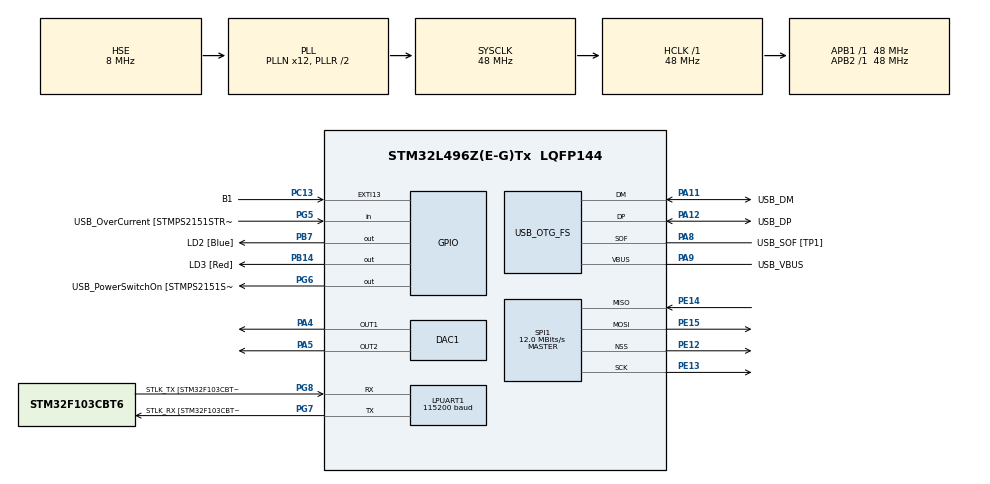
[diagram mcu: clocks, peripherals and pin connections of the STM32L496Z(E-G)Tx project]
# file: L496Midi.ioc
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DAC1.DAC_Channel-DAC_OUT2=DAC_CHANNEL_2
Dma.DAC_CH1.3.Direction=DMA_MEMORY_TO_PERIPH
Dma.DAC_CH1.3.Instance=DMA2_Channel4
Dma.DAC_CH1.3.MemDataAlignment=DMA_MDATAALIGN_HALFWORD
Dma.DAC_CH1.3.MemInc=DMA_MINC_ENABLE
Dma.DAC_CH1.3.Mode=DMA_NORMAL
Dma.DAC_CH1.3.PeriphDataAlignment=DMA_PDATAALIGN_HALFWORD
Dma.DAC_CH1.3.PeriphInc=DMA_PINC_DISABLE
Dma.DAC_CH1.3.Priority=DMA_PRIORITY_LOW
Dma.DAC_CH2.4.Direction=DMA_MEMORY_TO_PERIPH
Dma.DAC_CH2.4.Instance=DMA1_Channel4
Dma.DAC_CH2.4.MemDataAlignment=DMA_MDATAALIGN_HALFWORD
Dma.DAC_CH2.4.MemInc=DMA_MINC_ENABLE
Dma.DAC_CH2.4.Mode=DMA_NORMAL
Dma.DAC_CH2.4.PeriphDataAlignment=DMA_PDATAALIGN_HALFWORD
Dma.DAC_CH2.4.PeriphInc=DMA_PINC_DISABLE
Dma.DAC_CH2.4.Priority=DMA_PRIORITY_LOW
Dma.LPUART_TX.2.Direction=DMA_MEMORY_TO_PERIPH
Dma.LPUART_TX.2.Instance=DMA2_Channel6
Dma.LPUART_TX.2.MemDataAlignment=DMA_MDATAALIGN_BYTE
Dma.LPUART_TX.2.MemInc=DMA_MINC_ENABLE
Dma.LPUART_TX.2.Mode=DMA_CIRCULAR
Dma.LPUART_TX.2.PeriphDataAlignment=DMA_PDATAALIGN_BYTE
Dma.LPUART_TX.2.PeriphInc=DMA_PINC_DISABLE
Dma.LPUART_TX.2.Priority=DMA_PRIORITY_LOW
Dma.Request0=SPI1_RX
Dma.Request1=SPI1_TX
Dma.Request2=LPUART_TX
Dma.Request3=DAC_CH1
Dma.Request4=DAC_CH2
Dma.SPI1_RX.0.Direction=DMA_PERIPH_TO_MEMORY
Dma.SPI1_RX.0.Instance=DMA1_Channel2
Dma.SPI1_RX.0.MemDataAlignment=DMA_MDATAALIGN_BYTE
Dma.SPI1_RX.0.MemInc=DMA_MINC_ENABLE
Dma.SPI1_RX.0.Mode=DMA_NORMAL
Dma.SPI1_RX.0.PeriphDataAlignment=DMA_PDATAALIGN_BYTE
Dma.SPI1_RX.0.PeriphInc=DMA_PINC_DISABLE
Dma.SPI1_RX.0.Priority=DMA_PRIORITY_HIGH
Dma.SPI1_TX.1.Direction=DMA_MEMORY_TO_PERIPH
Dma.SPI1_TX.1.Instance=DMA1_Channel3
Dma.SPI1_TX.1.MemDataAlignment=DMA_MDATAALIGN_BYTE
Dma.SPI1_TX.1.MemInc=DMA_MINC_ENABLE
Dma.SPI1_TX.1.Mode=DMA_NORMAL
Dma.SPI1_TX.1.PeriphDataAlignment=DMA_PDATAALIGN_BYTE
Dma.SPI1_TX.1.PeriphInc=DMA_PINC_DISABLE
Dma.SPI1_TX.1.Priority=DMA_PRIORITY_HIGH
LPUART1.BaudRate=115200
LPUART1.Parity=UART_PARITY_EVEN
LPUART1.WordLength=UART_WORDLENGTH_9B
Mcu.Family=STM32L4
Mcu.Name=STM32L496Z(E-G)Tx
Mcu.Package=LQFP144
NVIC.DMA1_Channel2_IRQn=true\:0\:0\:false\:false\:true\:false
NVIC.DMA1_Channel3_IRQn=true\:0\:0\:false\:false\:true\:false
NVIC.DMA1_Channel4_IRQn=true\:0\:0\:false\:false\:true\:false
NVIC.DMA2_Channel4_IRQn=true\:0\:0\:false\:false\:true\:false
NVIC.DMA2_Channel6_IRQn=true\:0\:0\:false\:false\:true\:false
NVIC.OTG_FS_IRQn=true\:0\:0\:false\:false\:true\:false
NVIC.PriorityGroup=NVIC_PRIORITYGROUP_4
PA11.GPIO_Label=USB_DM
PA11.Mode=Device_Only
PA11.Signal=USB_OTG_FS_DM
PA12.GPIO_Label=USB_DP
PA12.Mode=Device_Only
PA12.Signal=USB_OTG_FS_DP
PA13\ (JTMS/SWDIO).GPIO_Label=TMS
PA13\ (JTMS/SWDIO).Mode=Trace_Asynchronous_SW
PA13\ (JTMS/SWDIO).Signal=SYS_JTMS-SWDIO
PA14\ (JTCK/SWCLK).GPIO_Label=TCK
PA14\ (JTCK/SWCLK).Mode=Trace_Asynchronous_SW
PA14\ (JTCK/SWCLK).Signal=SYS_JTCK-SWCLK
PA4.Signal=COMP_DAC11_group
PA5.Signal=COMP_DAC12_group
PA8.GPIO_Label=USB_SOF [TP1]
PA8.Mode=Activate_SOF_FS
PA8.Signal=USB_OTG_FS_SOF
PA9.GPIO_Label=USB_VBUS
PA9.Mode=Activate_VBUS
PA9.Signal=USB_OTG_FS_VBUS
PB14.GPIO_Label=LD3 [Red]
PB14.Signal=GPIO_Output
PB3\ (JTDO/TRACESWO).GPIO_Label=SWO
PB3\ (JTDO/TRACESWO).Mode=Trace_Asynchronous_SW
PB3\ (JTDO/TRACESWO).Signal=SYS_JTDO-SWO
PB7.GPIO_Label=LD2 [Blue]
PB7.Signal=GPIO_Output
PC13.GPIO_Label=B1
PC13.Signal=GPXTI13
PC14-OSC32_IN\ (PC14).Mode=LSE-External-Oscillator
PC14-OSC32_IN\ (PC14).Signal=RCC_OSC32_IN
PC15-OSC32_OUT\ (PC15).Mode=LSE-External-Oscillator
PC15-OSC32_OUT\ (PC15).Signal=RCC_OSC32_OUT
PE12.Mode=NSS_Signal_Hard_Output
PE12.Signal=SPI1_NSS
PE13.Mode=Full_Duplex_Master
PE13.Signal=SPI1_SCK
PE14.Mode=Full_Duplex_Master
PE14.Signal=SPI1_MISO
PE15.Mode=Full_Duplex_Master
PE15.Signal=SPI1_MOSI
PG5.GPIO_Label=USB_OverCurrent [STMPS2151STR_FAULT]
PG5.Signal=GPIO_Input
PG6.GPIO_Label=USB_PowerSwitchOn [STMPS2151STR_EN]
PG6.Signal=GPIO_Output
PG7.GPIO_Label=STLK_RX [STM32F103CBT6_PA3]
PG7.GPIO_Speed=GPIO_SPEED_FREQ_MEDIUM
PG7.Mode=Asynchronous
PG7.Signal=LPUART1_TX
PG8.GPIO_Label=STLK_TX [STM32F103CBT6_PA2]
PG8.GPIO_Speed=GPIO_SPEED_FREQ_MEDIUM
PG8.Mode=Asynchronous
PG8.Signal=LPUART1_RX
PH0-OSC_IN\ (PH0).Mode=HSE-External-Oscillator
PH0-OSC_IN\ (PH0).Signal=RCC_OSC_IN
PH1-OSC_OUT\ (PH1).Mode=HSE-External-Oscillator
PH1-OSC_OUT\ (PH1).Signal=RCC_OSC_OUT
ProjectManager.HeapSize=0x200
ProjectManager.StackSize=0x400
ProjectManager.TargetToolchain=TrueSTUDIO
RCC.48MHZClocksFreq_Value=24000000
RCC.ADCFreq_Value=48000000
RCC.AHBFreq_Value=48000000
RCC.APB1Freq_Value=48000000
RCC.APB1TimFreq_Value=48000000
RCC.APB2Freq_Value=48000000
RCC.APB2TimFreq_Value=48000000
RCC.CK48CLockSelection=RCC_USBCLKSOURCE_PLL
RCC.CortexFreq_Value=48000000
RCC.EnbaleCSS=true
RCC.HCLKFreq_Value=48000000
RCC.HSE_VALUE=8000000
RCC.HSI48_VALUE=48000000
RCC.HSI_VALUE=16000000
RCC.MSI_VALUE=4000000
RCC.PLLMUL=RCC_PLL_MUL9
RCC.PLLN=12
RCC.PLLSAI1N=12
RCC.PLLSourceVirtual=RCC_PLLSOURCE_HSE
RCC.PRESCALERUSB=RCC_USBCLKSOURCE_PLL_DIV1_5
RCC.SYSCLKFreq_VALUE=48000000
RCC.SYSCLKSource=RCC_SYSCLKSOURCE_PLLCLK
RCC.SYSCLKSourceVirtual=RCC_SYSCLKSOURCE_PLLCLK
RCC.USBFreq_Value=48000000
RCC.VCOOutputFreq_Value=96000000
SH.COMP_DAC11_group.0=DAC1_OUT1,DAC_OUT1
SH.COMP_DAC12_group.0=DAC1_OUT2,DAC_OUT2
SPI1.BaudRatePrescaler=SPI_BAUDRATEPRESCALER_4
SPI1.CalculateBaudRate=12.0 MBits/s
SPI1.DataSize=SPI_DATASIZE_8BIT
SPI1.Direction=SPI_DIRECTION_2LINES
SPI1.Mode=SPI_MODE_MASTER
SPI1.VirtualNSS=VM_NSSHARD
SPI1.VirtualType=VM_MASTER
USB_DEVICE.CLASS_NAME_FS=AUDIO
USB_DEVICE.USBD_DEBUG_LEVEL=3
USB_DEVICE.USBD_MAX_NUM_INTERFACES=1
USB_DEVICE.VirtualMode=Audio
USB_DEVICE.VirtualModeFS=Audio_FS
USB_OTG_FS.VirtualMode=Device_Only
VP_USB_DEVICE_VS_USB_DEVICE_AUDIO_FS.Mode=AUDIO_FS
board=NUCLEO-L496ZG

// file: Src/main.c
/**
  ******************************************************************************
  * @file           : main.c
  * @brief          : Main program body
  ******************************************************************************
  * This notice applies to any and all portions of this file
  * that are not between comment pairs USER CODE BEGIN and
  * USER CODE END. Other portions of this file, whether
  * inserted by the user or by software development tools
  * are owned by their respective copyright owners.
  *
  * Copyright (c) 2018 STMicroelectronics International N.V.
  * All rights reserved.
  *
  * Redistribution and use in source and binary forms, with or without
  * modification, are permitted, provided that the following conditions are met:
  *
  * 1. Redistribution of source code must retain the above copyright notice,
  *    this list of conditions and the following disclaimer.
  * 2. Redistributions in binary form must reproduce the above copyright notice,
  *    this list of conditions and the following disclaimer in the documentation
  *    and/or other materials provided with the distribution.
  * 3. Neither the name of STMicroelectronics nor the names of other
  *    contributors to this software may be used to endorse or promote products
  *    derived from this software without specific written permission.
  * 4. This software, including modifications and/or derivative works of this
  *    software, must execute solely and exclusively on microcontroller or
  *    microprocessor devices manufactured by or for STMicroelectronics.
  * 5. Redistribution and use of this software other than as permitted under
  *    this license is void and will automatically terminate your rights under
  *    this license.
  *
  * THIS SOFTWARE IS PROVIDED BY STMICROELECTRONICS AND CONTRIBUTORS "AS IS"
  * AND ANY EXPRESS, IMPLIED OR STATUTORY WARRANTIES, INCLUDING, BUT NOT
  * LIMITED TO, THE IMPLIED WARRANTIES OF MERCHANTABILITY, FITNESS FOR A
  * PARTICULAR PURPOSE AND NON-INFRINGEMENT OF THIRD PARTY INTELLECTUAL PROPERTY
  * RIGHTS ARE DISCLAIMED TO THE FULLEST EXTENT PERMITTED BY LAW. IN NO EVENT
  * SHALL STMICROELECTRONICS OR CONTRIBUTORS BE LIABLE FOR ANY DIRECT, INDIRECT,
  * INCIDENTAL, SPECIAL, EXEMPLARY, OR CONSEQUENTIAL DAMAGES (INCLUDING, BUT NOT
  * LIMITED TO, PROCUREMENT OF SUBSTITUTE GOODS OR SERVICES; LOSS OF USE, DATA,
  * OR PROFITS; OR BUSINESS INTERRUPTION) HOWEVER CAUSED AND ON ANY THEORY OF
  * LIABILITY, WHETHER IN CONTRACT, STRICT LIABILITY, OR TORT (INCLUDING
  * NEGLIGENCE OR OTHERWISE) ARISING IN ANY WAY OUT OF THE USE OF THIS SOFTWARE,
  * EVEN IF ADVISED OF THE POSSIBILITY OF SUCH DAMAGE.
  *
  ******************************************************************************
  */
#include "main.h"
#include "stm32l4xx_hal.h"
#include "dac.h"
#include "dma.h"
#include "usart.h"
#include "spi.h"
#include "usb_device.h"
#include "gpio.h"

/* USER CODE BEGIN PV */
/* Private variables ---------------------------------------------------------*/
uint8_t aTxBuffer[] = " Hello World! ";
/* USER CODE END PV */

void SystemClock_Config(void);

/* USER CODE BEGIN PFP */
/* Private function prototypes -----------------------------------------------*/
void USART1_SendMessage(void);

/* USER CODE END PFP */

int main(void)
{

  /* MCU Configuration----------------------------------------------------------*/

  /* Reset of all peripherals, Initializes the Flash interface and the Systick. */
  HAL_Init();

  /* Configure the system clock */
  SystemClock_Config();

  /* Initialize all configured peripherals */
  MX_GPIO_Init();
  MX_DMA_Init();
  MX_LPUART1_UART_Init();
  MX_SPI1_Init();
  MX_DAC1_Init();
  /* USER CODE BEGIN 2 */
  // todo - auto created by CubeMX -> uses USB_Audio instead of USB_Midi -> edit usb_device.c!
  //MX_USB_DEVICE_Init();
  /* USER CODE END 2 */

  /* Infinite loop */
  /* USER CODE BEGIN WHILE */
  while (1)
  {
	  HAL_GPIO_WritePin(LD3_GPIO_Port, LD3_Pin, GPIO_PIN_SET);
	  HAL_Delay(1000);
	  USART1_SendMessage();
	  HAL_GPIO_WritePin(LD3_GPIO_Port, LD3_Pin, GPIO_PIN_RESET);
	  HAL_Delay(1000);

  /* USER CODE END WHILE */

  }

}

void SystemClock_Config(void)
{

  RCC_OscInitTypeDef RCC_OscInitStruct;
  RCC_ClkInitTypeDef RCC_ClkInitStruct;
  RCC_PeriphCLKInitTypeDef PeriphClkInit;

    /**Initializes the CPU, AHB and APB busses clocks
    */
  RCC_OscInitStruct.OscillatorType = RCC_OSCILLATORTYPE_HSE;
  RCC_OscInitStruct.HSEState = RCC_HSE_ON;
  RCC_OscInitStruct.PLL.PLLState = RCC_PLL_ON;
  RCC_OscInitStruct.PLL.PLLSource = RCC_PLLSOURCE_HSE;
  RCC_OscInitStruct.PLL.PLLN = 12;
  RCC_OscInitStruct.PLL.PLLP = RCC_PLLP_DIV2;
  RCC_OscInitStruct.PLL.PLLQ = RCC_PLLQ_DIV2;
  RCC_OscInitStruct.PLL.PLLR = RCC_PLLR_DIV2;
  if (HAL_RCC_OscConfig(&RCC_OscInitStruct) != HAL_OK)
  {
    _Error_Handler(__FILE__, __LINE__);
  }

    /**Initializes the CPU, AHB and APB busses clocks
    */
  RCC_ClkInitStruct.ClockType = RCC_CLOCKTYPE_HCLK|RCC_CLOCKTYPE_SYSCLK
                              |RCC_CLOCKTYPE_PCLK1|RCC_CLOCKTYPE_PCLK2;
  RCC_ClkInitStruct.SYSCLKSource = RCC_SYSCLKSOURCE_PLLCLK;
  RCC_ClkInitStruct.AHBCLKDivider = RCC_SYSCLK_DIV1;
  RCC_ClkInitStruct.APB1CLKDivider = RCC_HCLK_DIV1;
  RCC_ClkInitStruct.APB2CLKDivider = RCC_HCLK_DIV1;

  if (HAL_RCC_ClockConfig(&RCC_ClkInitStruct, FLASH_LATENCY_2) != HAL_OK)
  {
    _Error_Handler(__FILE__, __LINE__);
  }

  PeriphClkInit.PeriphClockSelection = RCC_PERIPHCLK_LPUART1|RCC_PERIPHCLK_USB;
  PeriphClkInit.Lpuart1ClockSelection = RCC_LPUART1CLKSOURCE_PCLK1;
  PeriphClkInit.UsbClockSelection = RCC_USBCLKSOURCE_PLL;
  if (HAL_RCCEx_PeriphCLKConfig(&PeriphClkInit) != HAL_OK)
  {
    _Error_Handler(__FILE__, __LINE__);
  }

    /**Enables the Clock Security System
    */
  HAL_RCC_EnableCSS();

    /**Configure the main internal regulator output voltage
    */
  if (HAL_PWREx_ControlVoltageScaling(PWR_REGULATOR_VOLTAGE_SCALE1) != HAL_OK)
  {
    _Error_Handler(__FILE__, __LINE__);
  }

    /**Configure the Systick interrupt time
    */
  HAL_SYSTICK_Config(HAL_RCC_GetHCLKFreq()/1000);

    /**Configure the Systick
    */
  HAL_SYSTICK_CLKSourceConfig(SYSTICK_CLKSOURCE_HCLK);

  /* SysTick_IRQn interrupt configuration */
  HAL_NVIC_SetPriority(SysTick_IRQn, 0, 0);
}

/* USER CODE BEGIN 4 */

void USART1_SendMessage(void)
{
  if(HAL_UART_Transmit_DMA(&hlpuart1, (uint8_t*)aTxBuffer, TXBUFFERSIZE)!= HAL_OK)
  {
	Error_Handler();
  }
}

/**
  * @brief  Tx Transfer completed callback
  * @param  UartHandle: UART handle.
  * @retval None
  */
void HAL_UART_TxCpltCallback(UART_HandleTypeDef *UartHandle)
{
   HAL_UART_AbortTransmit(&hlpuart1);

}

/* USER CODE END 4 */

void _Error_Handler(char *file, int line)
{
  while(1)
  {
  }
}

/************************ (C) COPYRIGHT STMicroelectronics *****END OF FILE****/
